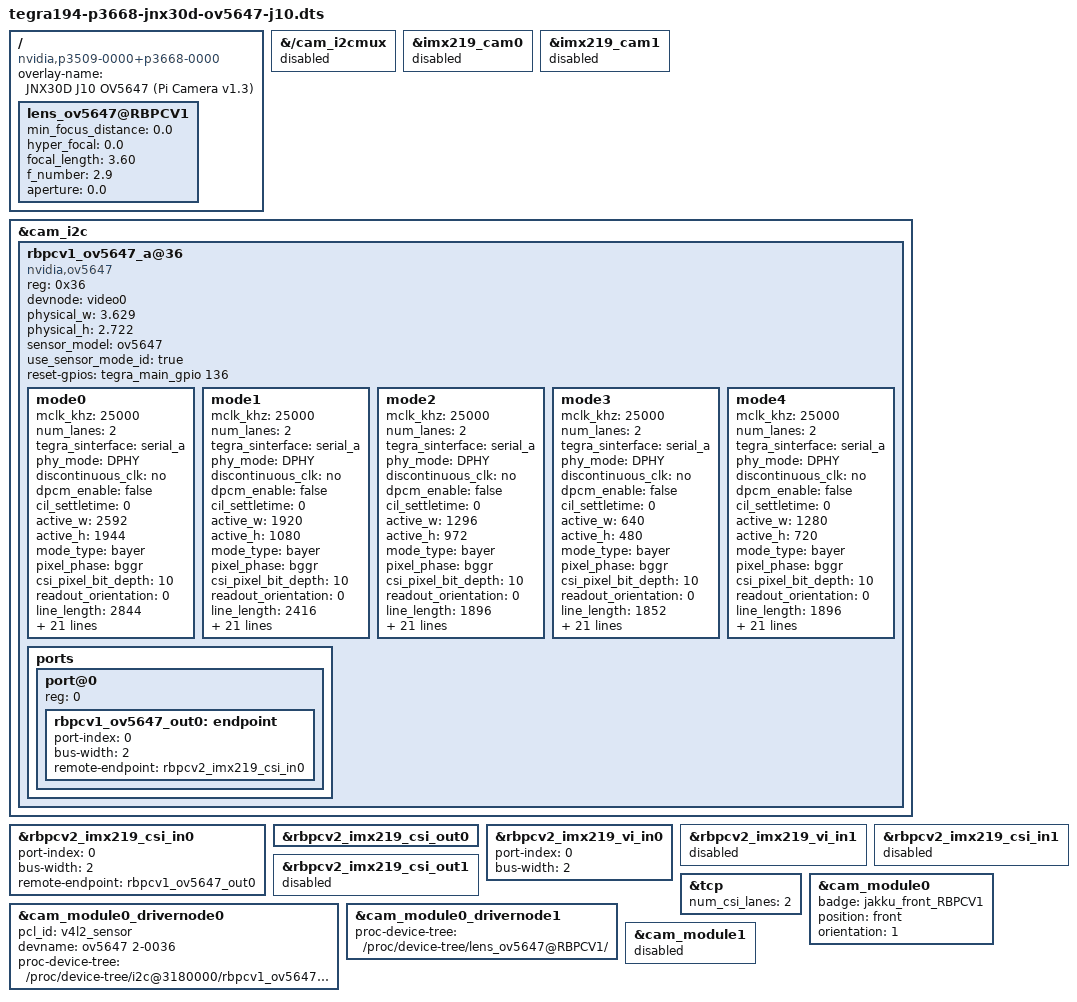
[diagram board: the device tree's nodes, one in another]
// SPDX-License-Identifier: GPL-2.0
/*
 * Raspberry Pi Camera v1.3 (OV5647) on Auvidea JNX30D connector J10
 * (CSI-A, 2 lanes, CAM_I2C = i2c-2) with Jetson Xavier NX, L4T R35.6.x.
 * Driver: ov5647.ko from github.com/akandr/ov5647-jetson (see upstream/COMMIT)
 * with driver/0001-ov5647-honour-reset-gpios-active-low.patch.
 *
 * Derived from dt/xavier/tegra194-p3668-ov5647-overlay.dts of that project
 * (Copyright (C) 2026 Artur Andrzejczak; (c) 2018-2023 NVIDIA, GPL-2.0).
 * Sensor modes are copied unchanged. Board-specific changes:
 *  - sensor on &cam_i2c (/i2c@3180000 = i2c-2) instead of the devkit mux
 *    bus i2c@0 (bus 9); the JNX30D has no camera I2C mux
 *  - enable on PR.00 (136), active HIGH (measured), instead of CAM0_PWDN PP.04 (0x7c)
 *  - devkit cam_i2cmux, both IMX219 nodes and graph channel 1 disabled
 *  - tegra-camera-platform devname "ov5647 2-0036"
 * No MCLK: the Pi Camera v1.3 has its own 25 MHz oscillator (mclk_khz 25000),
 * and J10 carries no clock pin. No regulator: J10 pin 1 is 3.3 V always-on.
 *
 * Build: dtc -@ -I dts -O dtb -o ov5647-j10.dtbo tegra194-p3668-jnx30d-ov5647-j10.dts
 */

/dts-v1/;
/plugin/;

/ {
	overlay-name = "JNX30D J10 OV5647 (Pi Camera v1.3)";
	compatible = "nvidia,p3509-0000+p3668-0000", "nvidia,p3509-0000+p3668-0001",
		     "nvidia,p3449-0000+p3668-0000", "nvidia,p3449-0000+p3668-0001";

	/* devkit-only I2C mux and the stock IMX219 nodes behind it */
	fragment@0 {
		target-path = "/cam_i2cmux";
		__overlay__ { status = "disabled"; };
	};
	fragment@1 {
		target = <&imx219_cam0>;
		__overlay__ { status = "disabled"; };
	};
	fragment@2 {
		target = <&imx219_cam1>;
		__overlay__ { status = "disabled"; };
	};

	/* sensor directly on CAM_I2C (i2c-2), address 0x36 */
	fragment@3 {
		target = <&cam_i2c>;
		__overlay__ {
			#address-cells = <1>;
			#size-cells = <0>;
			status = "okay";

			rbpcv1_ov5647_a@36 {
				compatible = "nvidia,ov5647";
				reg = <0x36>;

				devnode = "video0";

				/* pixel array: 2592 x 1944 at 1.4 um */
				physical_w = "3.629";
				physical_h = "2.722";

				sensor_model = "ov5647";
				use_sensor_mode_id = "true";

				/* JNX30D J10 pin 6 (camera enable, Pi pin 11) follows
				 * module pin 206 = PR.00 (TEGRA194_MAIN_GPIO(R,0) = 136).
				 * MEASURED on the drone 2026-10-19: PR.00 HIGH -> chip ID
				 * 0x5647, PR.00 LOW -> NACK. So camera ON = HIGH, flag 0
				 * (the manual describes an inverter; on our board it is not). */
				reset-gpios = <&tegra_main_gpio 136 0>;

				mode0 { /* OV5647_MODE_2592x1944_15FPS */
					mclk_khz = "25000";
					num_lanes = "2";
					tegra_sinterface = "serial_a";
					phy_mode = "DPHY";
					discontinuous_clk = "no";
					dpcm_enable = "false";
					cil_settletime = "0";

					active_w = "2592";
					active_h = "1944";
					mode_type = "bayer";
					pixel_phase = "bggr";
					csi_pixel_bit_depth = "10";
					readout_orientation = "0";
					line_length = "2844";
					inherent_gain = "1";
					mclk_multiplier = "3.50";
					pix_clk_hz = "87500000";

					gain_factor = "16";
					framerate_factor = "1000000";
					exposure_factor = "1000000";
					min_gain_val = "16";
					max_gain_val = "1023";
					step_gain_val = "1";
					default_gain = "16";
					min_hdr_ratio = "1";
					max_hdr_ratio = "1";
					min_framerate = "2000000";
					max_framerate = "15000000";
					step_framerate = "1";
					default_framerate = "15000000";
					min_exp_time = "131";
					max_exp_time = "500000";
					step_exp_time = "1";
					default_exp_time = "16666";

					embedded_metadata_height = "0";
				};
				mode1 { /* OV5647_MODE_1920x1080_30FPS */
					mclk_khz = "25000";
					num_lanes = "2";
					tegra_sinterface = "serial_a";
					phy_mode = "DPHY";
					discontinuous_clk = "no";
					dpcm_enable = "false";
					cil_settletime = "0";

					active_w = "1920";
					active_h = "1080";
					mode_type = "bayer";
					pixel_phase = "bggr";
					csi_pixel_bit_depth = "10";
					readout_orientation = "0";
					line_length = "2416";
					inherent_gain = "1";
					mclk_multiplier = "3.50";
					pix_clk_hz = "87500000";

					gain_factor = "16";
					framerate_factor = "1000000";
					exposure_factor = "1000000";
					min_gain_val = "16";
					max_gain_val = "1023";
					step_gain_val = "1";
					default_gain = "16";
					min_hdr_ratio = "1";
					max_hdr_ratio = "1";
					min_framerate = "2000000";
					max_framerate = "32800000";
					step_framerate = "1";
					default_framerate = "30000000";
					min_exp_time = "111";
					max_exp_time = "500000";
					step_exp_time = "1";
					default_exp_time = "16666";

					embedded_metadata_height = "0";
				};
				mode2 { /* OV5647_MODE_1296x972_30FPS */
					mclk_khz = "25000";
					num_lanes = "2";
					tegra_sinterface = "serial_a";
					phy_mode = "DPHY";
					discontinuous_clk = "no";
					dpcm_enable = "false";
					cil_settletime = "0";

					active_w = "1296";
					active_h = "972";
					mode_type = "bayer";
					pixel_phase = "bggr";
					csi_pixel_bit_depth = "10";
					readout_orientation = "0";
					line_length = "1896";
					inherent_gain = "1";
					mclk_multiplier = "3.50";
					pix_clk_hz = "87500000";

					gain_factor = "16";
					framerate_factor = "1000000";
					exposure_factor = "1000000";
					min_gain_val = "16";
					max_gain_val = "1023";
					step_gain_val = "1";
					default_gain = "16";
					min_hdr_ratio = "1";
					max_hdr_ratio = "1";
					min_framerate = "2000000";
					max_framerate = "32160000";
					step_framerate = "1";
					default_framerate = "30000000";
					min_exp_time = "87";
					max_exp_time = "500000";
					step_exp_time = "1";
					default_exp_time = "16666";

					embedded_metadata_height = "0";
				};
				mode3 { /* OV5647_MODE_640x480_90FPS */
					mclk_khz = "25000";
					num_lanes = "2";
					tegra_sinterface = "serial_a";
					phy_mode = "DPHY";
					discontinuous_clk = "no";
					dpcm_enable = "false";
					cil_settletime = "0";

					active_w = "640";
					active_h = "480";
					mode_type = "bayer";
					pixel_phase = "bggr";
					csi_pixel_bit_depth = "10";
					readout_orientation = "0";
					line_length = "1852";
					inherent_gain = "1";
					mclk_multiplier = "3.50";
					pix_clk_hz = "87500000";

					gain_factor = "16";
					framerate_factor = "1000000";
					exposure_factor = "1000000";
					min_gain_val = "16";
					max_gain_val = "1023";
					step_gain_val = "1";
					default_gain = "16";
					min_hdr_ratio = "1";
					max_hdr_ratio = "1";
					min_framerate = "2000000";
					max_framerate = "93740000";
					step_framerate = "1";
					default_framerate = "90000000";
					min_exp_time = "127";
					max_exp_time = "500000";
					step_exp_time = "1";
					default_exp_time = "16666";

					embedded_metadata_height = "0";
				};
				mode4 { /* OV5647_MODE_1280x720_60FPS */
					mclk_khz = "25000";
					num_lanes = "2";
					tegra_sinterface = "serial_a";
					phy_mode = "DPHY";
					discontinuous_clk = "no";
					dpcm_enable = "false";
					cil_settletime = "0";

					active_w = "1280";
					active_h = "720";
					mode_type = "bayer";
					pixel_phase = "bggr";
					csi_pixel_bit_depth = "10";
					readout_orientation = "0";
					line_length = "1896";
					inherent_gain = "1";
					mclk_multiplier = "3.50";
					pix_clk_hz = "87500000";

					gain_factor = "16";
					framerate_factor = "1000000";
					exposure_factor = "1000000";
					min_gain_val = "16";
					max_gain_val = "1023";
					step_gain_val = "1";
					default_gain = "16";
					min_hdr_ratio = "1";
					max_hdr_ratio = "1";
					min_framerate = "2000000";
					max_framerate = "60000000";
					step_framerate = "1";
					default_framerate = "60000000";
					min_exp_time = "87";
					max_exp_time = "500000";
					step_exp_time = "1";
					default_exp_time = "16666";

					embedded_metadata_height = "0";
				};


				ports {
					#address-cells = <1>;
					#size-cells = <0>;

					port@0 {
						reg = <0>;
						rbpcv1_ov5647_out0: endpoint {
							status = "okay";
							port-index = <0>;
							bus-width = <2>;
							remote-endpoint = <&rbpcv2_imx219_csi_in0>;
						};
					};
				};
			};
		};
	};

	/* graph channel 0: sensor -> NVCSI ch0 (brick A) -> VI port 0 */
	fragment@4 {
		target = <&rbpcv2_imx219_csi_in0>;
		__overlay__ {
			status = "okay";
			port-index = <0>;
			bus-width = <2>;
			remote-endpoint = <&rbpcv1_ov5647_out0>;
		};
	};
	fragment@5 {
		target = <&rbpcv2_imx219_csi_out0>;
		__overlay__ { status = "okay"; };
	};
	fragment@6 {
		target = <&rbpcv2_imx219_vi_in0>;
		__overlay__ {
			status = "okay";
			port-index = <0>;
			bus-width = <2>;
		};
	};

	/* graph channel 1 unused */
	fragment@7 {
		target = <&rbpcv2_imx219_vi_in1>;
		__overlay__ { status = "disabled"; };
	};
	fragment@8 {
		target = <&rbpcv2_imx219_csi_in1>;
		__overlay__ { status = "disabled"; };
	};
	fragment@9 {
		target = <&rbpcv2_imx219_csi_out1>;
		__overlay__ { status = "disabled"; };
	};

	/* tegra-camera-platform (Argus) */
	fragment@10 {
		target = <&tcp>;
		__overlay__ { num_csi_lanes = <2>; };
	};
	fragment@11 {
		target = <&cam_module0>;
		__overlay__ {
			status = "okay";
			badge = "jakku_front_RBPCV1";
			position = "front";
			orientation = "1";
		};
	};
	fragment@12 {
		target = <&cam_module0_drivernode0>;
		__overlay__ {
			status = "okay";
			pcl_id = "v4l2_sensor";
			devname = "ov5647 2-0036";
			proc-device-tree = "/proc/device-tree/i2c@3180000/rbpcv1_ov5647_a@36";
		};
	};
	fragment@13 {
		target = <&cam_module0_drivernode1>;
		__overlay__ {
			proc-device-tree = "/proc/device-tree/lens_ov5647@RBPCV1/";
		};
	};
	fragment@14 {
		target = <&cam_module1>;
		__overlay__ { status = "disabled"; };
	};

	/* fixed-focus Pi Camera v1 lens, reported by Argus */
	fragment@15 {
		target-path = "/";
		__overlay__ {
			lens_ov5647@RBPCV1 {
				min_focus_distance = "0.0";
				hyper_focal = "0.0";
				focal_length = "3.60";
				f_number = "2.9";
				aperture = "0.0";
			};
		};
	};
};
